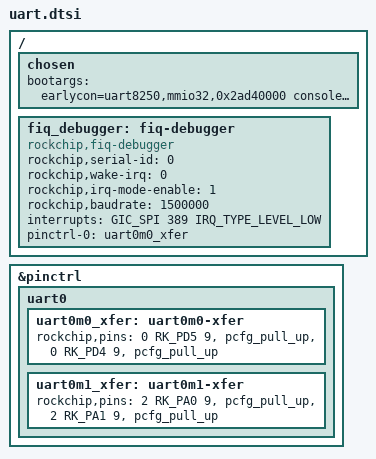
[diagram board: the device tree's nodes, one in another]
/{
	chosen: chosen {
		bootargs = "earlycon=uart8250,mmio32,0x2ad40000 console=ttyFIQ0 root=PARTUUID=614e0000-0000 rw rootwait rcupdate.rcu_expedited=1 rcu_nocbs=all";
	};

	fiq_debugger: fiq-debugger {
		compatible = "rockchip,fiq-debugger";
		rockchip,serial-id = <0>;
		rockchip,wake-irq = <0>;
		/* If enable uart uses irq instead of fiq */
		rockchip,irq-mode-enable = <1>;
		rockchip,baudrate = <1500000>;  /* Only 115200 and 1500000 */
		interrupts = <GIC_SPI 389 IRQ_TYPE_LEVEL_LOW>;
		pinctrl-names = "default";
		pinctrl-0 = <&uart0m0_xfer>;
		status = "okay";
	};
};

&pinctrl{
	uart0 {
		/omit-if-no-ref/
		uart0m0_xfer: uart0m0-xfer {
			rockchip,pins =
				/* uart0_rx_m0 */
				<0 RK_PD5 9 &pcfg_pull_up>,
				/* uart0_tx_m0 */
				<0 RK_PD4 9 &pcfg_pull_up>;
		};

		/omit-if-no-ref/
		uart0m1_xfer: uart0m1-xfer {
			rockchip,pins =
				/* uart0_rx_m1 */
				<2 RK_PA0 9 &pcfg_pull_up>,
				/* uart0_tx_m1 */
				<2 RK_PA1 9 &pcfg_pull_up>;
		};
	};

};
